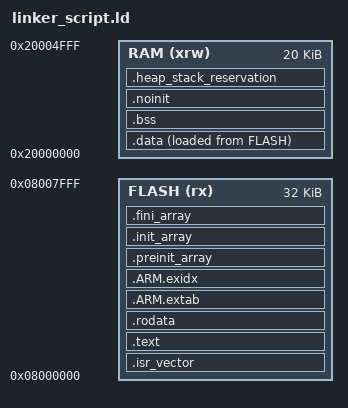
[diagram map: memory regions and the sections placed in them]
/* STM32F103C8: GCC, direct Flash boot, ST startup_stm32f103xb.s.
 * Heap/stack reservations are link-time minimums, not runtime guards.
 */
ENTRY(Reset_Handler)
MEMORY
{
  FLASH (rx)  : ORIGIN = 0x08000000, LENGTH = 32K
  RAM   (xrw) : ORIGIN = 0x20000000, LENGTH = 20K
}
_estack = ORIGIN(RAM) + LENGTH(RAM);
_Min_Heap_Size = 0x200;
_Min_Stack_Size = 0x400;
SECTIONS
{
  .isr_vector :
  {
    . = ALIGN(4);
    KEEP(*(.isr_vector))
    . = ALIGN(4);
  } > FLASH

  .text :
  {
    . = ALIGN(4);
    *(.text .text.*)
    *(.glue_7 .glue_7t)
    KEEP(*(.init))
    KEEP(*(.fini))
    *(.eh_frame .eh_frame.*)
    . = ALIGN(4);
    _etext = .;
  } > FLASH

  .rodata :
  {
    . = ALIGN(4);
    *(.rodata .rodata.*)
    . = ALIGN(4);
  } > FLASH

  .ARM.extab : { *(.ARM.extab* .gnu.linkonce.armextab.*) } > FLASH
  .ARM.exidx :
  {
    __exidx_start = .;
    *(.ARM.exidx* .gnu.linkonce.armexidx.*)
    __exidx_end = .;
  } > FLASH

  .preinit_array :
  {
    . = ALIGN(4);
    PROVIDE_HIDDEN(__preinit_array_start = .);
    KEEP(*(.preinit_array .preinit_array.*))
    PROVIDE_HIDDEN(__preinit_array_end = .);
  } > FLASH
  .init_array :
  {
    . = ALIGN(4);
    PROVIDE_HIDDEN(__init_array_start = .);
    KEEP(*(SORT(.init_array.*)))
    KEEP(*(.init_array))
    PROVIDE_HIDDEN(__init_array_end = .);
  } > FLASH
  .fini_array :
  {
    . = ALIGN(4);
    PROVIDE_HIDDEN(__fini_array_start = .);
    KEEP(*(SORT(.fini_array.*)))
    KEEP(*(.fini_array))
    PROVIDE_HIDDEN(__fini_array_end = .);
  } > FLASH

  _sidata = LOADADDR(.data);
  .data :
  {
    . = ALIGN(4);
    _sdata = .;
    *(.data .data.*)
    *(.RamFunc .RamFunc.*)
    . = ALIGN(4);
    _edata = .;
  } > RAM AT> FLASH

  .bss (NOLOAD) :
  {
    . = ALIGN(4);
    _sbss = .;
    __bss_start__ = .;
    *(.bss .bss.*)
    *(COMMON)
    . = ALIGN(4);
    _ebss = .;
    __bss_end__ = .;
  } > RAM

  .noinit (NOLOAD) :
  {
    . = ALIGN(4);
    *(.noinit .noinit.*)
    . = ALIGN(4);
  } > RAM

  .heap_stack_reservation (NOLOAD) :
  {
    . = ALIGN(8);
    PROVIDE(end = .);
    PROVIDE(_end = .);
    __HeapBase = .;
    . += _Min_Heap_Size;
    __HeapLimit = .;
    . += _Min_Stack_Size;
    . = ALIGN(8);
  } > RAM
  __StackLimit = _estack - _Min_Stack_Size;
  ASSERT(__HeapLimit <= __StackLimit, "RAM overflow: heap overlaps reserved stack")

  .ARM.attributes 0 : { *(.ARM.attributes) }
}
